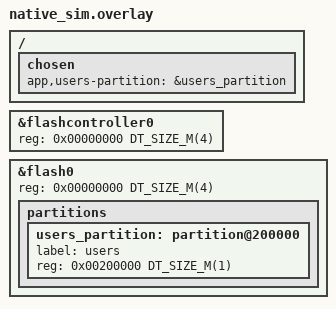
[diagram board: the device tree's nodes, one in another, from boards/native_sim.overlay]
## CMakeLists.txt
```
# SPDX-License-Identifier: Apache-2.0
cmake_minimum_required(VERSION 3.20.0)
set(BOARD_ROOT "${CMAKE_CURRENT_LIST_DIR}/../..")
# The library under test: the in-house gzm/ module of this repository.
list(APPEND ZEPHYR_EXTRA_MODULES ${CMAKE_CURRENT_LIST_DIR}/../../gzm)

find_package(Zephyr REQUIRED HINTS $ENV{ZEPHYR_BASE})
project(test_fs_mgr)

target_sources(app PRIVATE src/main.c src/wdt_feed.c)
```

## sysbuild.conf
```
# Sysbuild configuration file.

# Enable MCUboot bootloader
SB_CONFIG_BOOTLOADER_MCUBOOT=y

# MCUboot upgrade mode: SWAP using scratch partition.
# Supports different sector sizes between slots (internal 128 KB vs
# external QSPI NOR 4 KB) and enables automatic rollback.
SB_CONFIG_MCUBOOT_MODE_SWAP_SCRATCH=y

# Signed images (ECDSA P-256). Demo key generated locally by
# tools/keys/genkeys.sh. Never commit a production key.
SB_CONFIG_BOOT_SIGNATURE_TYPE_ECDSA_P256=y
SB_CONFIG_BOOT_SIGNATURE_KEY_FILE="${APP_DIR}/../../tools/keys/demo-ecdsa-p256.pem"

# Image encryption (ECIES P-256): the image stored in slot1 (external
# QSPI NOR) travels and rests encrypted; MCUboot decrypts during swap.
SB_CONFIG_BOOT_ENCRYPTION=y
SB_CONFIG_BOOT_ENCRYPTION_KEY_FILE="${APP_DIR}/../../tools/keys/demo-encryption-p256.pem"
```

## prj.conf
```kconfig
CONFIG_ZTEST=y
CONFIG_LOG=y

# LittleFS on the same partition as the app (chosen app,users-partition)
CONFIG_FLASH=y
CONFIG_FLASH_MAP=y
CONFIG_FLASH_PAGE_LAYOUT=y
CONFIG_FILE_SYSTEM=y
CONFIG_FILE_SYSTEM_LITTLEFS=y
CONFIG_FILE_SYSTEM_MKFS=y
CONFIG_HEAP_MEM_POOL_SIZE=16384

# The library under test (gzm/ module)
CONFIG_GZM_FS_MGR=y

# LittleFS mount/format runs in main (suite setup): 1 KB default overflows
# on the board with the SPI NOR; same size as tests/user_mgr
CONFIG_MAIN_STACK_SIZE=8192
CONFIG_ZTEST_STACK_SIZE=8192
```

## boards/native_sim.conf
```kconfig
# The user store lives on the simulated flash (RAM-backed NOR).
CONFIG_FLASH_SIMULATOR=y
```

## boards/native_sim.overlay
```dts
/* Same partition as the app on native_sim: the stock storage
 * partition is only 16 KB, so grow the simulated flash to 4 MB and give
 * the users a 1 MB partition after the default layout. */

/ {
	chosen {
		app,users-partition = &users_partition;
	};
};

&flashcontroller0 {
	reg = <0x00000000 DT_SIZE_M(4)>;
};

&flash0 {
	reg = <0x00000000 DT_SIZE_M(4)>;

	partitions {
		users_partition: partition@200000 {
			label = "users";
			reg = <0x00200000 DT_SIZE_M(1)>;
		};
	};
};
```

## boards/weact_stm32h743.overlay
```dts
/*
 * Hardware test build: console/shell on UART4 (PA0/PA1), the same
 * adapter used for firmware updates doubles as the Twister
 * --device-serial port. The app image links at slot0 (sysbuild).
 */

/ {
	chosen {
		zephyr,console = &uart4;
		zephyr,shell-uart = &uart4;
		zephyr,code-partition = &slot0_partition;
		app,users-partition = &storage_partition;
	};
};

&uart4 {
	pinctrl-0 = <&uart4_tx_pa0 &uart4_rx_pa1>;
	pinctrl-names = "default";
	current-speed = <115200>;
	status = "okay";
};
```

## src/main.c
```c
/*
 * Copyright (c) 2026 GZM Embarcados
 *
 * Unit tests for gzm/fs_mgr on LittleFS: atomic save + load, recovery of
 * an interrupted save, directories, listings, partial reads/writes and
 * disk space.
 */

#include <errno.h>
#include <string.h>

#include <zephyr/fs/fs.h>
#include <zephyr/fs/littlefs.h>
#include <zephyr/storage/flash_map.h>
#include <zephyr/ztest.h>

#include <gzm/fs_mgr.h>

#define MNT "/lfs"
#define TEST_DIR MNT "/t"

FS_LITTLEFS_DECLARE_DEFAULT_CONFIG(test_lfs);

static struct fs_mount_t mnt = {
	.type = FS_LITTLEFS,
	.fs_data = &test_lfs,
	.storage_dev = (void *)DT_FIXED_PARTITION_ID(DT_CHOSEN(app_users_partition)),
	.mnt_point = MNT,
};

/* Size of a file, or a negative errno when it does not exist */
static int size_of(const char *name)
{
	int size = 0;
	int err = fs_mgr_get_file_size(TEST_DIR, name, &size);

	return err ? err : size;
}

static void *suite_setup(void)
{
	zassert_ok(fs_mgr_init(&mnt), "fs_mgr_init on %s", MNT);
	return NULL;
}

static void before_each(void *fixture)
{
	ARG_UNUSED(fixture);
	zassert_ok(fs_mgr_mkdir_if_not_exists(TEST_DIR));
	(void)fs_mgr_delete_files_of_path(TEST_DIR);
}

ZTEST_SUITE(fs_mgr, NULL, suite_setup, before_each, NULL, NULL);

/* Save + load ---------------------------------------------------------- */

ZTEST(fs_mgr, test_save_and_load_roundtrip)
{
	/* Larger than the 512 B write chunk: exercises the chunked write */
	static uint8_t out[1500];
	static uint8_t in[1500];

	for (size_t i = 0; i < sizeof(out); i++) {
		out[i] = (uint8_t)(i * 7);
	}
	zassert_ok(fs_mgr_save_file(TEST_DIR, "a.bin", out, sizeof(out)));
	zassert_equal(fs_mgr_load_file(TEST_DIR, "a.bin", in, sizeof(in)), sizeof(in));
	zassert_mem_equal(in, out, sizeof(out));
	zassert_equal(size_of("a.bin.new"), -ENOENT, "temporary file left behind");
}

ZTEST(fs_mgr, test_save_replaces_the_content)
{
	char in[16] = {0};

	zassert_ok(fs_mgr_save_file(TEST_DIR, "a.txt", "first", 5));
	zassert_ok(fs_mgr_save_file(TEST_DIR, "a.txt", "2nd", 3));
	zassert_equal(fs_mgr_load_file(TEST_DIR, "a.txt", in, sizeof(in)), 3);
	zassert_str_equal(in, "2nd");
}

ZTEST(fs_mgr, test_save_with_full_path)
{
	char in[8] = {0};

	zassert_ok(fs_mgr_save_file(NULL, TEST_DIR "/b.txt", "abc", 3));
	zassert_equal(fs_mgr_read_file(TEST_DIR, "b.txt", in, sizeof(in)), 3);
	zassert_str_equal(in, "abc");
}

ZTEST(fs_mgr, test_save_bad_args)
{
	zassert_equal(fs_mgr_save_file(TEST_DIR, NULL, "x", 1), -EINVAL);
	zassert_equal(fs_mgr_save_file(TEST_DIR, "x", NULL, 1), -EINVAL);
	zassert_equal(fs_mgr_save_file(TEST_DIR, "x", "x", -1), -EINVAL);
}

ZTEST(fs_mgr, test_load_missing_file)
{
	char in[4];

	zassert_equal(fs_mgr_load_file(TEST_DIR, "nope.bin", in, sizeof(in)), -ENOENT);
}

/* Interrupted save ----------------------------------------------------- */

ZTEST(fs_mgr, test_recover_only_the_new_file)
{
	/* Power cut after the old file was removed, before the rename */
	char in[8] = {0};

	zassert_equal(fs_mgr_pwrite(TEST_DIR "/c.txt.new", "new", 3, 0, FS_MGR_MODE_W_CREATE), 3);
	zassert_equal(fs_mgr_load_file(TEST_DIR, "c.txt", in, sizeof(in)), 3);
	zassert_str_equal(in, "new");
	zassert_equal(size_of("c.txt.new"), -ENOENT);
}

ZTEST(fs_mgr, test_recover_new_file_wins_over_old)
{
	/* Power cut after the new file was written, before the old was removed */
	char in[8] = {0};

	zassert_ok(fs_mgr_save_file(TEST_DIR, "c.txt", "old", 3));
	zassert_equal(fs_mgr_pwrite(TEST_DIR "/c.txt.new", "new", 3, 0, FS_MGR_MODE_W_CREATE), 3);
	zassert_equal(fs_mgr_load_file(TEST_DIR, "c.txt", in, sizeof(in)), 3);
	zassert_str_equal(in, "new");
	zassert_equal(size_of("c.txt.new"), -ENOENT);
}

ZTEST(fs_mgr, test_recover_without_new_file_keeps_the_old)
{
	char in[8] = {0};

	zassert_ok(fs_mgr_save_file(TEST_DIR, "c.txt", "old", 3));
	zassert_ok(fs_mgr_recover(TEST_DIR, "c.txt"));
	zassert_equal(fs_mgr_load_file(TEST_DIR, "c.txt", in, sizeof(in)), 3);
	zassert_str_equal(in, "old");
	zassert_equal(fs_mgr_recover(TEST_DIR, NULL), -EINVAL);
}

/* Directories ---------------------------------------------------------- */

ZTEST(fs_mgr, test_mkdir_creates_every_level_and_is_idempotent)
{
	struct fs_dirent ent;

	zassert_ok(fs_mgr_mkdir_if_not_exists(TEST_DIR "/x/y/z"));
	zassert_ok(fs_mgr_mkdir_if_not_exists(TEST_DIR "/x/y/z"));
	zassert_ok(fs_stat(TEST_DIR "/x/y/z", &ent));
	zassert_equal(ent.type, FS_DIR_ENTRY_DIR);
}

ZTEST(fs_mgr, test_mkdir_errors)
{
	zassert_ok(fs_mgr_save_file(TEST_DIR, "file", "x", 1));
	zassert_equal(fs_mgr_mkdir_if_not_exists(TEST_DIR "/file"), -EEXIST, "a file is not a dir");
	zassert_equal(fs_mgr_mkdir_if_not_exists(NULL), -EINVAL);
	zassert_equal(fs_mgr_mkdir_if_not_exists(""), -EINVAL);
}

ZTEST(fs_mgr, test_count_list_and_search)
{
	struct fs_mgr_file_entry list[8];
	char name[32];
	int n = 0;
	int total = 0;
	int size = 0;

	zassert_ok(fs_mgr_save_file(TEST_DIR, "f1", "0123456789", 10));
	zassert_ok(fs_mgr_save_file(TEST_DIR, "f2", "01234567890123456789", 20));
	zassert_ok(fs_mgr_save_file(TEST_DIR, "f3", "012345678901234567890123456789", 30));
	zassert_ok(fs_mgr_mkdir_if_not_exists(TEST_DIR "/sub"));

	zassert_ok(fs_mgr_get_num_files_in_dir(TEST_DIR, &n, &total));
	zassert_equal(n, 3, "directories do not count");
	zassert_equal(total, 60);

	zassert_equal(fs_mgr_list_files(TEST_DIR, list, ARRAY_SIZE(list)), 3);
	zassert_equal(fs_mgr_list_files(TEST_DIR, list, 2), 2, "stops at max_entries");
	zassert_equal(fs_mgr_list_files(TEST_DIR, NULL, 2), -EINVAL);

	zassert_ok(fs_mgr_search_file_in_dir(TEST_DIR, name, sizeof(name), &size, &n));
	zassert_equal(n, 3);
	zassert_true(size > 0);
}

ZTEST(fs_mgr, test_empty_and_missing_dirs)
{
	char name[32];
	int size = 0;
	int n = 0;

	zassert_equal(fs_mgr_search_file_in_dir(TEST_DIR, name, sizeof(name), &size, &n), -ENOENT);
	zassert_equal(n, 0);
	zassert_equal(fs_mgr_get_num_files_in_dir(MNT "/missing", &n, &size), -ENOEXEC);
}

/* Delete + release space ----------------------------------------------- */

ZTEST(fs_mgr, test_delete)
{
	int n = 0;
	int total = 0;

	zassert_ok(fs_mgr_save_file(TEST_DIR, "d1", "x", 1));
	zassert_ok(fs_mgr_save_file(TEST_DIR, "d2", "y", 1));

	zassert_ok(fs_mgr_delete_file(TEST_DIR, "d1"));
	zassert_equal(size_of("d1"), -ENOENT);
	zassert_not_equal(fs_mgr_delete_file(TEST_DIR, "d1"), 0, "already deleted");

	zassert_ok(fs_mgr_delete_files_of_path(TEST_DIR));
	zassert_ok(fs_mgr_get_num_files_in_dir(TEST_DIR, &n, &total));
	zassert_equal(n, 0);
}

ZTEST(fs_mgr, test_release_space_deletes_until_enough)
{
	static uint8_t buf[100];
	int n = 0;
	int total = 0;

	zassert_ok(fs_mgr_save_file(TEST_DIR, "r1", buf, sizeof(buf)));
	zassert_ok(fs_mgr_save_file(TEST_DIR, "r2", buf, sizeof(buf)));
	zassert_ok(fs_mgr_save_file(TEST_DIR, "r3", buf, sizeof(buf)));

	/* 150 bytes: two files of 100 go, one stays */
	zassert_ok(fs_mgr_release_space_in_path(TEST_DIR, 150));
	zassert_ok(fs_mgr_get_num_files_in_dir(TEST_DIR, &n, &total));
	zassert_equal(n, 1);
	zassert_equal(fs_mgr_release_space_in_path(TEST_DIR, 0), -EINVAL);
}

/* Partial read/write --------------------------------------------------- */

ZTEST(fs_mgr, test_pwrite_pread_at_offset)
{
	char in[16] = {0};

	zassert_equal(fs_mgr_pwrite(TEST_DIR "/p", "0123456789", 10, 0, FS_MGR_MODE_W_CREATE), 10);
	zassert_equal(fs_mgr_pwrite(TEST_DIR "/p", "AB", 2, 3, FS_MGR_MODE_RW), 2);
	zassert_equal(fs_mgr_pread(TEST_DIR "/p", in, 4, 2, FS_MGR_MODE_R), 4);
	zassert_mem_equal(in, "2AB5", 4);

	zassert_equal(fs_mgr_pwrite(TEST_DIR "/p", "XY", 2, FS_MGR_OFFSET_END, FS_MGR_MODE_W_OPEN), 2);
	zassert_equal(size_of("p"), 12);
	memset(in, 0, sizeof(in));
	zassert_equal(fs_mgr_pread(TEST_DIR "/p", in, sizeof(in), 0, FS_MGR_MODE_R), 12);
	zassert_str_equal(in, "012AB56789XY");
}

ZTEST(fs_mgr, test_pread_pwrite_errors)
{
	char in[4];

	zassert_equal(fs_mgr_pread(TEST_DIR "/missing", in, sizeof(in), 0, FS_MGR_MODE_R), -ENOENT);
	zassert_equal(fs_mgr_pread(TEST_DIR "/p", in, sizeof(in), 0, FS_MGR_MODE_W_CREATE), -EINVAL,
		      "read with a write-only mode");
	zassert_equal(fs_mgr_pwrite(TEST_DIR "/p", "x", 1, 0, FS_MGR_MODE_R), -EINVAL,
		      "write with a read-only mode");
	zassert_equal(fs_mgr_pwrite(TEST_DIR "/p", "x", 0, 0, FS_MGR_MODE_W_CREATE), -EINVAL);
	zassert_equal(fs_mgr_pread(NULL, in, sizeof(in), 0, FS_MGR_MODE_R), -EINVAL);
}

ZTEST(fs_mgr, test_preallocate)
{
	zassert_ok(fs_mgr_preallocate(TEST_DIR "/big", 4096));
	zassert_equal(size_of("big"), 4096);
	zassert_equal(fs_mgr_preallocate(NULL, 1), -EINVAL);
}

/* Disk space ----------------------------------------------------------- */

ZTEST(fs_mgr, test_mem_info_adds_up)
{
	float size = 0;
	float free_space = 0;
	float used = 0;

	zassert_ok(fs_mgr_mem_info(&mnt, FS_MGR_MEM_SIZE, &size));
	zassert_ok(fs_mgr_mem_info(&mnt, FS_MGR_MEM_FREE_SPACE, &free_space));
	zassert_ok(fs_mgr_mem_info(&mnt, FS_MGR_MEM_USED_SPACE, &used));
	zassert_true(size > 0 && free_space > 0 && used > 0);
	zassert_within(used + free_space, size, 1.0f);

	zassert_equal(fs_mgr_mem_info(&mnt, FS_MGR_MEM_MAX, &size), -ENOTSUP);
	zassert_equal(fs_mgr_mem_info(&mnt, FS_MGR_MEM_SIZE, NULL), -EINVAL);
}

/* Mount ---------------------------------------------------------------- */

ZTEST(fs_mgr, test_files_survive_unmount_and_mount)
{
	char in[8] = {0};

	zassert_ok(fs_mgr_save_file(TEST_DIR, "keep", "kept", 4));
	zassert_ok(fs_mgr_deinit(&mnt));
	zassert_ok(fs_mgr_init(&mnt));
	zassert_equal(fs_mgr_load_file(TEST_DIR, "keep", in, sizeof(in)), 4);
	zassert_str_equal(in, "kept");
}

ZTEST(fs_mgr, test_format_wipes_everything)
{
	char in[4];

	zassert_ok(fs_mgr_save_file(TEST_DIR, "gone", "x", 1));
	zassert_ok(fs_mgr_format(&mnt));
	zassert_equal(fs_mgr_load_file(TEST_DIR, "gone", in, sizeof(in)), -ENOENT);
}
```

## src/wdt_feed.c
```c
/* Copyright (c) 2026 GZM Embarcados
 * SPDX-License-Identifier: Apache-2.0
 *
 * On the board MCUboot starts the IWDG (20 s) and it cannot be stopped:
 * the test image must keep feeding it, like the app does in main.c,
 * or the board resets in the middle of the longer tests.
 */

#include <zephyr/device.h>
#include <zephyr/drivers/watchdog.h>
#include <zephyr/init.h>
#include <zephyr/kernel.h>

#if defined(CONFIG_WATCHDOG) && DT_NODE_HAS_STATUS(DT_ALIAS(watchdog0), okay)
static const struct device *const wdt = DEVICE_DT_GET(DT_ALIAS(watchdog0));

static void wdt_feed_fn(struct k_work *work);
static K_WORK_DELAYABLE_DEFINE(wdt_feed_work, wdt_feed_fn);

static void wdt_feed_fn(struct k_work *work)
{
	wdt_feed(wdt, 0);
	k_work_schedule(&wdt_feed_work, K_SECONDS(1));
}

static int wdt_feed_start(void)
{
	k_work_schedule(&wdt_feed_work, K_NO_WAIT);
	return 0;
}

SYS_INIT(wdt_feed_start, APPLICATION, 0);
#endif
```
